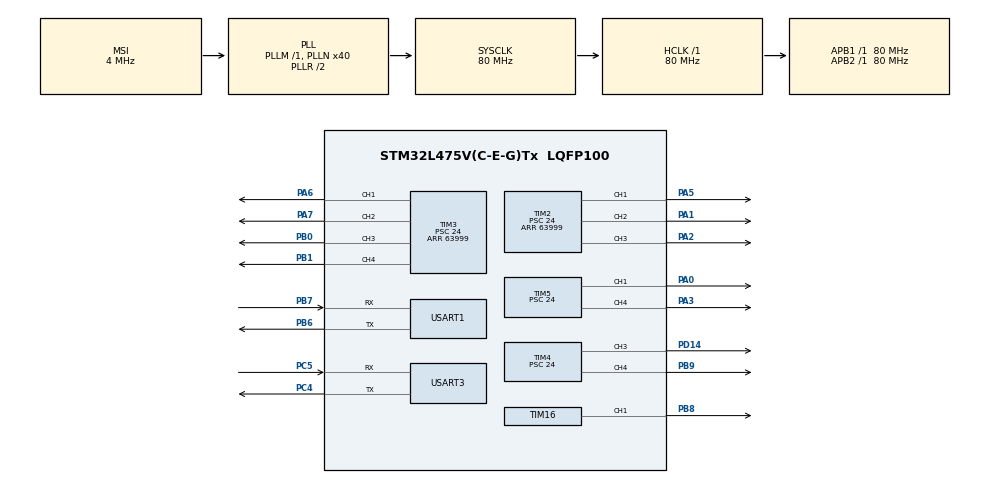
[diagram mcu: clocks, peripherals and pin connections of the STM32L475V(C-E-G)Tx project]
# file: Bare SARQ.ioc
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Mcu.Family=STM32L4
Mcu.Name=STM32L475V(C-E-G)Tx
Mcu.Package=LQFP100
NVIC.PriorityGroup=NVIC_PRIORITYGROUP_4
NVIC.USART1_IRQn=true\:0\:0\:false\:false\:true\:true\:true\:true
NVIC.USART3_IRQn=true\:0\:0\:false\:false\:true\:true\:true\:true
PA0.Signal=S_TIM5_CH1
PA1.Signal=S_TIM2_CH2
PA13\ (JTMS-SWDIO).Mode=Serial_Wire
PA13\ (JTMS-SWDIO).Signal=SYS_JTMS-SWDIO
PA14\ (JTCK-SWCLK).Mode=Serial_Wire
PA14\ (JTCK-SWCLK).Signal=SYS_JTCK-SWCLK
PA2.Signal=S_TIM2_CH3
PA3.Signal=S_TIM5_CH4
PA5.Signal=S_TIM2_CH1
PA6.Signal=S_TIM3_CH1
PA7.Signal=S_TIM3_CH2
PB0.Signal=S_TIM3_CH3
PB1.Signal=S_TIM3_CH4
PB6.Mode=Asynchronous
PB6.Signal=USART1_TX
PB7.Mode=Asynchronous
PB7.Signal=USART1_RX
PB8.Signal=S_TIM16_CH1
PB9.Signal=S_TIM4_CH4
PC4.Mode=Asynchronous
PC4.Signal=USART3_TX
PC5.Mode=Asynchronous
PC5.Signal=USART3_RX
PD14.Signal=S_TIM4_CH3
ProjectManager.HeapSize=0x200
ProjectManager.StackSize=0x400
ProjectManager.TargetToolchain=STM32CubeIDE
RCC.ADCFreq_Value=48000000
RCC.AHBFreq_Value=80000000
RCC.APB1Freq_Value=80000000
RCC.APB1TimFreq_Value=80000000
RCC.APB2Freq_Value=80000000
RCC.APB2TimFreq_Value=80000000
RCC.CortexFreq_Value=80000000
RCC.HCLKFreq_Value=80000000
RCC.HSE_VALUE=8000000
RCC.HSI_VALUE=16000000
RCC.LSE_VALUE=32768
RCC.MSI_VALUE=4000000
RCC.PLLN=40
RCC.PLLSAI1N=24
RCC.SYSCLKFreq_VALUE=80000000
RCC.SYSCLKSource=RCC_SYSCLKSOURCE_PLLCLK
RCC.USBFreq_Value=48000000
RCC.VCOOutputFreq_Value=160000000
SH.S_TIM16_CH1.0=TIM16_CH1,PWM Generation1 CH1
SH.S_TIM2_CH1.0=TIM2_CH1,PWM Generation1 CH1
SH.S_TIM2_CH2.0=TIM2_CH2,PWM Generation2 CH2
SH.S_TIM2_CH3.0=TIM2_CH3,PWM Generation3 CH3
SH.S_TIM3_CH1.0=TIM3_CH1,PWM Generation1 CH1
SH.S_TIM3_CH2.0=TIM3_CH2,PWM Generation2 CH2
SH.S_TIM3_CH3.0=TIM3_CH3,PWM Generation3 CH3
SH.S_TIM3_CH4.0=TIM3_CH4,PWM Generation4 CH4
SH.S_TIM4_CH3.0=TIM4_CH3,PWM Generation3 CH3
SH.S_TIM4_CH4.0=TIM4_CH4,PWM Generation4 CH4
SH.S_TIM5_CH1.0=TIM5_CH1,PWM Generation1 CH1
SH.S_TIM5_CH4.0=TIM5_CH4,PWM Generation4 CH4
TIM16.Channel=TIM_CHANNEL_1
TIM16.Period=63999
TIM16.Prescaler=24
TIM2.Channel-PWM\ Generation1\ CH1=TIM_CHANNEL_1
TIM2.Channel-PWM\ Generation2\ CH2=TIM_CHANNEL_2
TIM2.Channel-PWM\ Generation3\ CH3=TIM_CHANNEL_3
TIM2.Channel-PWM\ Generation4\ No\ Output=TIM_CHANNEL_4
TIM2.Period=63999
TIM2.Prescaler=24
TIM3.Channel-PWM\ Generation1\ CH1=TIM_CHANNEL_1
TIM3.Channel-PWM\ Generation2\ CH2=TIM_CHANNEL_2
TIM3.Channel-PWM\ Generation3\ CH3=TIM_CHANNEL_3
TIM3.Channel-PWM\ Generation4\ CH4=TIM_CHANNEL_4
TIM3.Period=63999
TIM3.Prescaler=24
TIM4.Channel-PWM\ Generation3\ CH3=TIM_CHANNEL_3
TIM4.Channel-PWM\ Generation4\ CH4=TIM_CHANNEL_4
TIM4.Period=63999
TIM4.Prescaler=24
TIM5.Channel-PWM\ Generation1\ CH1=TIM_CHANNEL_1
TIM5.Channel-PWM\ Generation4\ CH4=TIM_CHANNEL_4
TIM5.Period=63999
TIM5.Prescaler=24
USART1.VirtualMode-Asynchronous=VM_ASYNC
USART3.VirtualMode-Asynchronous=VM_ASYNC
VP_TIM16_VS_ClockSourceINT.Mode=Enable_Timer
VP_TIM2_VS_ClockSourceINT.Mode=Internal
VP_TIM2_VS_no_output4.Mode=PWM Generation4 No Output
VP_TIM3_VS_ClockSourceINT.Mode=Internal
VP_TIM4_VS_ClockSourceINT.Mode=Internal
VP_TIM5_VS_ClockSourceINT.Mode=Internal
board=custom

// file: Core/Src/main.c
/* USER CODE BEGIN Header */
/**
  ******************************************************************************
  * @file           : main.c
  * @brief          : Main program body
  ******************************************************************************
  * @attention
  *
  * Copyright (c) 2025 STMicroelectronics.
  * All rights reserved.
  *
  * This software is licensed under terms that can be found in the LICENSE file
  * in the root directory of this software component.
  * If no LICENSE file comes with this software, it is provided AS-IS.
  *
  ******************************************************************************
  */
/* USER CODE END Header */
#include "main.h"

/* USER CODE BEGIN Includes */
#include "userApp.h"
/* USER CODE END Includes */

TIM_HandleTypeDef htim2;
TIM_HandleTypeDef htim3;
TIM_HandleTypeDef htim4;
TIM_HandleTypeDef htim5;
TIM_HandleTypeDef htim16;

UART_HandleTypeDef huart1;
UART_HandleTypeDef huart3;

void SystemClock_Config(void);
static void MX_GPIO_Init(void);
static void MX_USART1_UART_Init(void);
static void MX_TIM2_Init(void);
static void MX_TIM3_Init(void);
static void MX_TIM4_Init(void);
static void MX_TIM5_Init(void);
static void MX_USART3_UART_Init(void);
static void MX_TIM16_Init(void);

int main(void)
{

  /* MCU Configuration--------------------------------------------------------*/

  /* Reset of all peripherals, Initializes the Flash interface and the Systick. */
   HAL_Init();

  /* Configure the system clock */
  SystemClock_Config();

  /* Initialize all configured peripherals */
  MX_GPIO_Init();
  MX_USART1_UART_Init();
  MX_TIM2_Init();
  MX_TIM3_Init();
  MX_TIM4_Init();
  MX_TIM5_Init();
  MX_USART3_UART_Init();
  MX_TIM16_Init();
  /* USER CODE BEGIN 2 */
  userApp();
  /* USER CODE END 2 */

  /* Infinite loop */
  while (1)
  {

  }
}

void SystemClock_Config(void)
{
  RCC_OscInitTypeDef RCC_OscInitStruct = {0};
  RCC_ClkInitTypeDef RCC_ClkInitStruct = {0};

  /** Configure the main internal regulator output voltage
  */
  if (HAL_PWREx_ControlVoltageScaling(PWR_REGULATOR_VOLTAGE_SCALE1) != HAL_OK)
  {
    Error_Handler();
  }

  /** Initializes the RCC Oscillators according to the specified parameters
  * in the RCC_OscInitTypeDef structure.
  */
  RCC_OscInitStruct.OscillatorType = RCC_OSCILLATORTYPE_MSI;
  RCC_OscInitStruct.MSIState = RCC_MSI_ON;
  RCC_OscInitStruct.MSICalibrationValue = 0;
  RCC_OscInitStruct.MSIClockRange = RCC_MSIRANGE_6;
  RCC_OscInitStruct.PLL.PLLState = RCC_PLL_ON;
  RCC_OscInitStruct.PLL.PLLSource = RCC_PLLSOURCE_MSI;
  RCC_OscInitStruct.PLL.PLLM = 1;
  RCC_OscInitStruct.PLL.PLLN = 40;
  RCC_OscInitStruct.PLL.PLLP = RCC_PLLP_DIV7;
  RCC_OscInitStruct.PLL.PLLQ = RCC_PLLQ_DIV2;
  RCC_OscInitStruct.PLL.PLLR = RCC_PLLR_DIV2;
  if (HAL_RCC_OscConfig(&RCC_OscInitStruct) != HAL_OK)
  {
    Error_Handler();
  }

  /** Initializes the CPU, AHB and APB buses clocks
  */
  RCC_ClkInitStruct.ClockType = RCC_CLOCKTYPE_HCLK|RCC_CLOCKTYPE_SYSCLK
                              |RCC_CLOCKTYPE_PCLK1|RCC_CLOCKTYPE_PCLK2;
  RCC_ClkInitStruct.SYSCLKSource = RCC_SYSCLKSOURCE_PLLCLK;
  RCC_ClkInitStruct.AHBCLKDivider = RCC_SYSCLK_DIV1;
  RCC_ClkInitStruct.APB1CLKDivider = RCC_HCLK_DIV1;
  RCC_ClkInitStruct.APB2CLKDivider = RCC_HCLK_DIV1;

  if (HAL_RCC_ClockConfig(&RCC_ClkInitStruct, FLASH_LATENCY_4) != HAL_OK)
  {
    Error_Handler();
  }
}

static void MX_TIM2_Init(void)
{

  TIM_ClockConfigTypeDef sClockSourceConfig = {0};
  TIM_MasterConfigTypeDef sMasterConfig = {0};
  TIM_OC_InitTypeDef sConfigOC = {0};

  htim2.Instance = TIM2;
  htim2.Init.Prescaler = 24;
  htim2.Init.CounterMode = TIM_COUNTERMODE_UP;
  htim2.Init.Period = 63999;
  htim2.Init.ClockDivision = TIM_CLOCKDIVISION_DIV1;
  htim2.Init.AutoReloadPreload = TIM_AUTORELOAD_PRELOAD_DISABLE;
  if (HAL_TIM_Base_Init(&htim2) != HAL_OK)
  {
    Error_Handler();
  }
  sClockSourceConfig.ClockSource = TIM_CLOCKSOURCE_INTERNAL;
  if (HAL_TIM_ConfigClockSource(&htim2, &sClockSourceConfig) != HAL_OK)
  {
    Error_Handler();
  }
  if (HAL_TIM_PWM_Init(&htim2) != HAL_OK)
  {
    Error_Handler();
  }
  sMasterConfig.MasterOutputTrigger = TIM_TRGO_RESET;
  sMasterConfig.MasterSlaveMode = TIM_MASTERSLAVEMODE_DISABLE;
  if (HAL_TIMEx_MasterConfigSynchronization(&htim2, &sMasterConfig) != HAL_OK)
  {
    Error_Handler();
  }
  sConfigOC.OCMode = TIM_OCMODE_PWM1;
  sConfigOC.Pulse = 0;
  sConfigOC.OCPolarity = TIM_OCPOLARITY_HIGH;
  sConfigOC.OCFastMode = TIM_OCFAST_DISABLE;
  if (HAL_TIM_PWM_ConfigChannel(&htim2, &sConfigOC, TIM_CHANNEL_1) != HAL_OK)
  {
    Error_Handler();
  }
  if (HAL_TIM_PWM_ConfigChannel(&htim2, &sConfigOC, TIM_CHANNEL_2) != HAL_OK)
  {
    Error_Handler();
  }
  if (HAL_TIM_PWM_ConfigChannel(&htim2, &sConfigOC, TIM_CHANNEL_3) != HAL_OK)
  {
    Error_Handler();
  }
  if (HAL_TIM_PWM_ConfigChannel(&htim2, &sConfigOC, TIM_CHANNEL_4) != HAL_OK)
  {
    Error_Handler();
  }
  HAL_TIM_MspPostInit(&htim2);

}

static void MX_TIM3_Init(void)
{

  TIM_ClockConfigTypeDef sClockSourceConfig = {0};
  TIM_MasterConfigTypeDef sMasterConfig = {0};
  TIM_OC_InitTypeDef sConfigOC = {0};

  htim3.Instance = TIM3;
  htim3.Init.Prescaler = 24;
  htim3.Init.CounterMode = TIM_COUNTERMODE_UP;
  htim3.Init.Period = 63999;
  htim3.Init.ClockDivision = TIM_CLOCKDIVISION_DIV1;
  htim3.Init.AutoReloadPreload = TIM_AUTORELOAD_PRELOAD_DISABLE;
  if (HAL_TIM_Base_Init(&htim3) != HAL_OK)
  {
    Error_Handler();
  }
  sClockSourceConfig.ClockSource = TIM_CLOCKSOURCE_INTERNAL;
  if (HAL_TIM_ConfigClockSource(&htim3, &sClockSourceConfig) != HAL_OK)
  {
    Error_Handler();
  }
  if (HAL_TIM_PWM_Init(&htim3) != HAL_OK)
  {
    Error_Handler();
  }
  sMasterConfig.MasterOutputTrigger = TIM_TRGO_RESET;
  sMasterConfig.MasterSlaveMode = TIM_MASTERSLAVEMODE_DISABLE;
  if (HAL_TIMEx_MasterConfigSynchronization(&htim3, &sMasterConfig) != HAL_OK)
  {
    Error_Handler();
  }
  sConfigOC.OCMode = TIM_OCMODE_PWM1;
  sConfigOC.Pulse = 0;
  sConfigOC.OCPolarity = TIM_OCPOLARITY_HIGH;
  sConfigOC.OCFastMode = TIM_OCFAST_DISABLE;
  if (HAL_TIM_PWM_ConfigChannel(&htim3, &sConfigOC, TIM_CHANNEL_1) != HAL_OK)
  {
    Error_Handler();
  }
  if (HAL_TIM_PWM_ConfigChannel(&htim3, &sConfigOC, TIM_CHANNEL_2) != HAL_OK)
  {
    Error_Handler();
  }
  if (HAL_TIM_PWM_ConfigChannel(&htim3, &sConfigOC, TIM_CHANNEL_3) != HAL_OK)
  {
    Error_Handler();
  }
  if (HAL_TIM_PWM_ConfigChannel(&htim3, &sConfigOC, TIM_CHANNEL_4) != HAL_OK)
  {
    Error_Handler();
  }
  HAL_TIM_MspPostInit(&htim3);

}

static void MX_TIM4_Init(void)
{

  TIM_ClockConfigTypeDef sClockSourceConfig = {0};
  TIM_MasterConfigTypeDef sMasterConfig = {0};
  TIM_OC_InitTypeDef sConfigOC = {0};

  htim4.Instance = TIM4;
  htim4.Init.Prescaler = 24;
  htim4.Init.CounterMode = TIM_COUNTERMODE_UP;
  htim4.Init.Period = 63999;
  htim4.Init.ClockDivision = TIM_CLOCKDIVISION_DIV1;
  htim4.Init.AutoReloadPreload = TIM_AUTORELOAD_PRELOAD_DISABLE;
  if (HAL_TIM_Base_Init(&htim4) != HAL_OK)
  {
    Error_Handler();
  }
  sClockSourceConfig.ClockSource = TIM_CLOCKSOURCE_INTERNAL;
  if (HAL_TIM_ConfigClockSource(&htim4, &sClockSourceConfig) != HAL_OK)
  {
    Error_Handler();
  }
  if (HAL_TIM_PWM_Init(&htim4) != HAL_OK)
  {
    Error_Handler();
  }
  sMasterConfig.MasterOutputTrigger = TIM_TRGO_RESET;
  sMasterConfig.MasterSlaveMode = TIM_MASTERSLAVEMODE_DISABLE;
  if (HAL_TIMEx_MasterConfigSynchronization(&htim4, &sMasterConfig) != HAL_OK)
  {
    Error_Handler();
  }
  sConfigOC.OCMode = TIM_OCMODE_PWM1;
  sConfigOC.Pulse = 0;
  sConfigOC.OCPolarity = TIM_OCPOLARITY_HIGH;
  sConfigOC.OCFastMode = TIM_OCFAST_DISABLE;
  if (HAL_TIM_PWM_ConfigChannel(&htim4, &sConfigOC, TIM_CHANNEL_3) != HAL_OK)
  {
    Error_Handler();
  }
  if (HAL_TIM_PWM_ConfigChannel(&htim4, &sConfigOC, TIM_CHANNEL_4) != HAL_OK)
  {
    Error_Handler();
  }
  HAL_TIM_MspPostInit(&htim4);

}

static void MX_TIM5_Init(void)
{

  TIM_ClockConfigTypeDef sClockSourceConfig = {0};
  TIM_MasterConfigTypeDef sMasterConfig = {0};
  TIM_OC_InitTypeDef sConfigOC = {0};

  htim5.Instance = TIM5;
  htim5.Init.Prescaler = 24;
  htim5.Init.CounterMode = TIM_COUNTERMODE_UP;
  htim5.Init.Period = 63999;
  htim5.Init.ClockDivision = TIM_CLOCKDIVISION_DIV1;
  htim5.Init.AutoReloadPreload = TIM_AUTORELOAD_PRELOAD_DISABLE;
  if (HAL_TIM_Base_Init(&htim5) != HAL_OK)
  {
    Error_Handler();
  }
  sClockSourceConfig.ClockSource = TIM_CLOCKSOURCE_INTERNAL;
  if (HAL_TIM_ConfigClockSource(&htim5, &sClockSourceConfig) != HAL_OK)
  {
    Error_Handler();
  }
  if (HAL_TIM_PWM_Init(&htim5) != HAL_OK)
  {
    Error_Handler();
  }
  sMasterConfig.MasterOutputTrigger = TIM_TRGO_RESET;
  sMasterConfig.MasterSlaveMode = TIM_MASTERSLAVEMODE_DISABLE;
  if (HAL_TIMEx_MasterConfigSynchronization(&htim5, &sMasterConfig) != HAL_OK)
  {
    Error_Handler();
  }
  sConfigOC.OCMode = TIM_OCMODE_PWM1;
  sConfigOC.Pulse = 0;
  sConfigOC.OCPolarity = TIM_OCPOLARITY_HIGH;
  sConfigOC.OCFastMode = TIM_OCFAST_DISABLE;
  if (HAL_TIM_PWM_ConfigChannel(&htim5, &sConfigOC, TIM_CHANNEL_1) != HAL_OK)
  {
    Error_Handler();
  }
  if (HAL_TIM_PWM_ConfigChannel(&htim5, &sConfigOC, TIM_CHANNEL_4) != HAL_OK)
  {
    Error_Handler();
  }
  HAL_TIM_MspPostInit(&htim5);

}

static void MX_TIM16_Init(void)
{

  TIM_OC_InitTypeDef sConfigOC = {0};
  TIM_BreakDeadTimeConfigTypeDef sBreakDeadTimeConfig = {0};

  htim16.Instance = TIM16;
  htim16.Init.Prescaler = 24;
  htim16.Init.CounterMode = TIM_COUNTERMODE_UP;
  htim16.Init.Period = 63999;
  htim16.Init.ClockDivision = TIM_CLOCKDIVISION_DIV1;
  htim16.Init.RepetitionCounter = 0;
  htim16.Init.AutoReloadPreload = TIM_AUTORELOAD_PRELOAD_DISABLE;
  if (HAL_TIM_Base_Init(&htim16) != HAL_OK)
  {
    Error_Handler();
  }
  if (HAL_TIM_PWM_Init(&htim16) != HAL_OK)
  {
    Error_Handler();
  }
  sConfigOC.OCMode = TIM_OCMODE_PWM1;
  sConfigOC.Pulse = 0;
  sConfigOC.OCPolarity = TIM_OCPOLARITY_HIGH;
  sConfigOC.OCNPolarity = TIM_OCNPOLARITY_HIGH;
  sConfigOC.OCFastMode = TIM_OCFAST_DISABLE;
  sConfigOC.OCIdleState = TIM_OCIDLESTATE_RESET;
  sConfigOC.OCNIdleState = TIM_OCNIDLESTATE_RESET;
  if (HAL_TIM_PWM_ConfigChannel(&htim16, &sConfigOC, TIM_CHANNEL_1) != HAL_OK)
  {
    Error_Handler();
  }
  sBreakDeadTimeConfig.OffStateRunMode = TIM_OSSR_DISABLE;
  sBreakDeadTimeConfig.OffStateIDLEMode = TIM_OSSI_DISABLE;
  sBreakDeadTimeConfig.LockLevel = TIM_LOCKLEVEL_OFF;
  sBreakDeadTimeConfig.DeadTime = 0;
  sBreakDeadTimeConfig.BreakState = TIM_BREAK_DISABLE;
  sBreakDeadTimeConfig.BreakPolarity = TIM_BREAKPOLARITY_HIGH;
  sBreakDeadTimeConfig.AutomaticOutput = TIM_AUTOMATICOUTPUT_DISABLE;
  if (HAL_TIMEx_ConfigBreakDeadTime(&htim16, &sBreakDeadTimeConfig) != HAL_OK)
  {
    Error_Handler();
  }
  HAL_TIM_MspPostInit(&htim16);

}

static void MX_USART1_UART_Init(void)
{

  huart1.Instance = USART1;
  huart1.Init.BaudRate = 115200;
  huart1.Init.WordLength = UART_WORDLENGTH_8B;
  huart1.Init.StopBits = UART_STOPBITS_1;
  huart1.Init.Parity = UART_PARITY_NONE;
  huart1.Init.Mode = UART_MODE_TX_RX;
  huart1.Init.HwFlowCtl = UART_HWCONTROL_NONE;
  huart1.Init.OverSampling = UART_OVERSAMPLING_16;
  huart1.Init.OneBitSampling = UART_ONE_BIT_SAMPLE_DISABLE;
  huart1.AdvancedInit.AdvFeatureInit = UART_ADVFEATURE_NO_INIT;
  if (HAL_UART_Init(&huart1) != HAL_OK)
  {
    Error_Handler();
  }

}

static void MX_USART3_UART_Init(void)
{

  huart3.Instance = USART3;
  huart3.Init.BaudRate = 115200;
  huart3.Init.WordLength = UART_WORDLENGTH_8B;
  huart3.Init.StopBits = UART_STOPBITS_1;
  huart3.Init.Parity = UART_PARITY_NONE;
  huart3.Init.Mode = UART_MODE_TX_RX;
  huart3.Init.HwFlowCtl = UART_HWCONTROL_NONE;
  huart3.Init.OverSampling = UART_OVERSAMPLING_16;
  huart3.Init.OneBitSampling = UART_ONE_BIT_SAMPLE_DISABLE;
  huart3.AdvancedInit.AdvFeatureInit = UART_ADVFEATURE_NO_INIT;
  if (HAL_UART_Init(&huart3) != HAL_OK)
  {
    Error_Handler();
  }

}

static void MX_GPIO_Init(void)
{

  /* GPIO Ports Clock Enable */
  __HAL_RCC_GPIOA_CLK_ENABLE();
  __HAL_RCC_GPIOC_CLK_ENABLE();
  __HAL_RCC_GPIOB_CLK_ENABLE();
  __HAL_RCC_GPIOD_CLK_ENABLE();

}

void Error_Handler(void)
{
  __disable_irq();
  while (1)
  {
  }
}
